AUTOSAR XML (schema 4-0-3)
standard types defined: Boolean, uint8, UInt16, UInt32, UInt8
package /AUTOSAR_Platform/DataConstrs
  range DC_Boolean: raw 0..1
  range DC_UInt16: raw 0..65535
  range DC_UInt8: raw 0..255
package /PATAC/Facility/DataTypes/Implementation
  compu method COMPU_Boolean: 0=FALSE, 1=TRUE
  unit NoUnit: factor-si-to-unit=1, offset-si-to-unit=0
package /PATAC/MSM/ComponentTypes
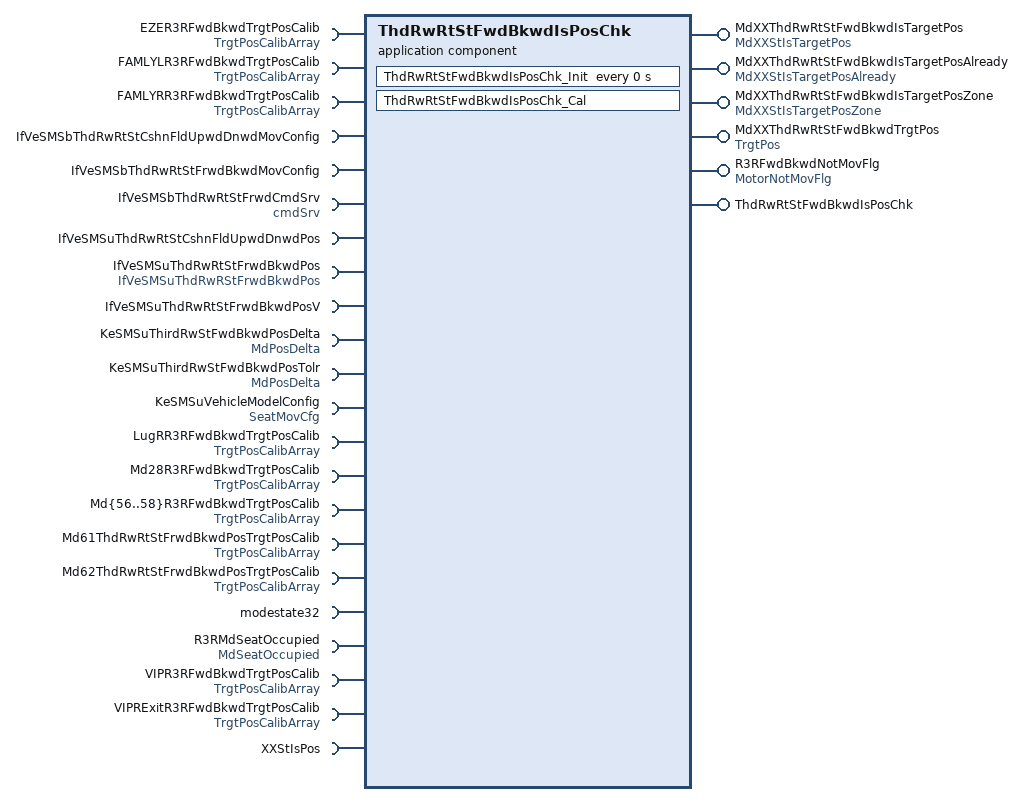
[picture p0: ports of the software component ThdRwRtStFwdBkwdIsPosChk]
  application sw component type ThdRwRtStFwdBkwdIsPosChk
    6 x provide port:
      MdXXThdRwRtStFwdBkwdIsTargetPos: nonqueued-sender-com-spec=data-element=MdXXStIsTargetPos/Val, provided-interface=MdXXStIsTargetPos
      MdXXThdRwRtStFwdBkwdIsTargetPosAlready: nonqueued-sender-com-spec=data-element=MdXXStIsTargetPosAlready/Val, provided-interface=MdXXStIsTargetPosAlready
      MdXXThdRwRtStFwdBkwdIsTargetPosZone: nonqueued-sender-com-spec=data-element=MdXXStIsTargetPosZone/Val, provided-interface=MdXXStIsTargetPosZone
      MdXXThdRwRtStFwdBkwdTrgtPos: nonqueued-sender-com-spec{data-element=TrgtPos/Val, init-value=4095}, provided-interface=TrgtPos
      R3RFwdBkwdNotMovFlg: nonqueued-sender-com-spec{data-element=MotorNotMovFlg/Val, init-value=0}, provided-interface=MotorNotMovFlg
      ThdRwRtStFwdBkwdIsPosChk: server-com-spec{operation=Cal, queue-length=1}, provided-interface=ThdRwRtStFwdBkwdIsPosChk
    24 x require port:
      EZER3RFwdBkwdTrgtPosCalib: nonqueued-receiver-com-spec{data-element=TrgtPosArray, filter=data-filter-type=ALWAYS, init-value=[4095, 4095, 4095]}, required-interface=TrgtPosCalibArray
      FAMLYLR3RFwdBkwdTrgtPosCalib: nonqueued-receiver-com-spec{data-element=TrgtPosArray, filter=data-filter-type=ALWAYS, init-value=[4095, 4095, 4095]}, required-interface=TrgtPosCalibArray
      FAMLYRR3RFwdBkwdTrgtPosCalib: nonqueued-receiver-com-spec{data-element=TrgtPosArray, filter=data-filter-type=ALWAYS, init-value=[4095, 4095, 4095]}, required-interface=TrgtPosCalibArray
      IfVeSMSbThdRwRtStCshnFldUpwdDnwdMovConfig: nonqueued-receiver-com-spec{data-element=IfVeSMSbThdRwRtStCshnFldUpwdDnwdMovConfig/Val, filter=data-filter-type=ALWAYS, init-value=0}, required-interface=IfVeSMSbThdRwRtStCshnFldUpwdDnwdMovConfig
      IfVeSMSbThdRwRtStFrwdBkwdMovConfig: nonqueued-receiver-com-spec{data-element=IfVeSMSbThdRwRtStFrwdBkwdMovConfig/Val, filter=data-filter-type=ALWAYS, init-value=0}, required-interface=IfVeSMSbThdRwRtStFrwdBkwdMovConfig
      IfVeSMSbThdRwRtStFrwdCmdSrv: nonqueued-receiver-com-spec{data-element=cmdSrv/Val, filter=data-filter-type=ALWAYS, init-value=1}, required-interface=cmdSrv
      IfVeSMSuThdRwRtStCshnFldUpwdDnwdPos: nonqueued-receiver-com-spec{data-element=IfVeSMSuThdRwRtStCshnFldUpwdDnwdPos/Val, filter=data-filter-type=ALWAYS, init-value=0}, required-interface=IfVeSMSuThdRwRtStCshnFldUpwdDnwdPos
      IfVeSMSuThdRwRtStFrwdBkwdPos: nonqueued-receiver-com-spec{data-element=IfVeSMSuThdRwRStFrwdBkwdPos/Val, filter=data-filter-type=ALWAYS, init-value=0}, required-interface=IfVeSMSuThdRwRStFrwdBkwdPos
      IfVeSMSuThdRwRtStFrwdBkwdPosV: nonqueued-receiver-com-spec{data-element=IfVeSMSuThdRwRtStFrwdBkwdPosV/Val, filter=data-filter-type=ALWAYS, init-value=0}, required-interface=IfVeSMSuThdRwRtStFrwdBkwdPosV
      KeSMSuThirdRwStFwdBkwdPosDelta: parameter-require-com-spec{init-value=150, parameter=MdPosDelta/Val}, required-interface=MdPosDelta
      KeSMSuThirdRwStFwdBkwdPosTolr: parameter-require-com-spec{init-value=150, parameter=MdPosDelta/Val}, required-interface=MdPosDelta
      KeSMSuVehicleModelConfig: parameter-require-com-spec{init-value=2, parameter=SeatMovCfg/Val}, required-interface=SeatMovCfg
      LugRR3RFwdBkwdTrgtPosCalib: nonqueued-receiver-com-spec{data-element=TrgtPosArray, filter=data-filter-type=ALWAYS, init-value=[4095, 4095, 4095]}, required-interface=TrgtPosCalibArray
      Md28R3RFwdBkwdTrgtPosCalib: nonqueued-receiver-com-spec{data-element=TrgtPosArray, filter=data-filter-type=ALWAYS, init-value=[4095, 4095, 4095]}, required-interface=TrgtPosCalibArray
      Md{56..58}R3RFwdBkwdTrgtPosCalib: nonqueued-receiver-com-spec{data-element=TrgtPosArray, filter=data-filter-type=ALWAYS, init-value=[4095, 4095, 4095]}, required-interface=TrgtPosCalibArray
      Md61ThdRwRtStFrwdBkwdPosTrgtPosCalib: nonqueued-receiver-com-spec{data-element=TrgtPosArray, filter=data-filter-type=ALWAYS, init-value=[4095, 4095, 4095]}, required-interface=TrgtPosCalibArray
      Md62ThdRwRtStFrwdBkwdPosTrgtPosCalib: nonqueued-receiver-com-spec{data-element=TrgtPosArray, filter=data-filter-type=ALWAYS, init-value=[4095, 4095, 4095]}, required-interface=TrgtPosCalibArray
      modestate32: nonqueued-receiver-com-spec{data-element=modestate32/Val, filter=data-filter-type=ALWAYS, init-value=0}, required-interface=modestate32
      R3RMdSeatOccupied: nonqueued-receiver-com-spec{data-element=MdSeatOccupied/Val, filter=data-filter-type=ALWAYS, init-value=0}, required-interface=MdSeatOccupied
      VIPR3RFwdBkwdTrgtPosCalib: nonqueued-receiver-com-spec{data-element=TrgtPosArray, filter=data-filter-type=ALWAYS, init-value=[4095, 4095, 4095]}, required-interface=TrgtPosCalibArray
      VIPRExitR3RFwdBkwdTrgtPosCalib: nonqueued-receiver-com-spec{data-element=TrgtPosArray, filter=data-filter-type=ALWAYS, init-value=[4095, 4095, 4095]}, required-interface=TrgtPosCalibArray
      XXStIsPos: client-com-spec=Get, required-interface=XXStIsPos
    behavior ThdRwRtStFwdBkwdIsPosChk_InternalBehavior
      operation invoked event OIT_ThdRwRtStFwdBkwdIsPosChk_Cal_ThdRwRtStFwdBkwdIsPosChk_Cal: start-on-event=ThdRwRtStFwdBkwdIsPosChk_Cal, operation=ThdRwRtStFwdBkwdIsPosChk.Cal
      timing event ThdRwRtStFwdBkwdIsPosChk_InitEvent: start-on-event=ThdRwRtStFwdBkwdIsPosChk_Init, period=0
      runnable ThdRwRtStFwdBkwdIsPosChk_Cal
        data-receive-point-by-arguments:
          20 x access:
            REC_EZER3RFwdBkwdTrgtPosCalib_TrgtPosArray: accessed-variable=EZER3RFwdBkwdTrgtPosCalib.TrgtPosArray
            REC_FAMLYLR3RFwdBkwdTrgtPosCalib_TrgtPosArray: accessed-variable=FAMLYLR3RFwdBkwdTrgtPosCalib.TrgtPosArray
            REC_FAMLYRR3RFwdBkwdTrgtPosCalib_TrgtPosArray: accessed-variable=FAMLYRR3RFwdBkwdTrgtPosCalib.TrgtPosArray
            REC_IfVeSMSbThdRwRtStCshnFldUpwdDnwdMovConfig_Val: accessed-variable=IfVeSMSbThdRwRtStCshnFldUpwdDnwdMovConfig.Val
            REC_IfVeSMSbThdRwRtStFrwdBkwdMovConfig_Val: accessed-variable=IfVeSMSbThdRwRtStFrwdBkwdMovConfig.Val
            REC_IfVeSMSbThdRwRtStFrwdCmdSrv_Val: accessed-variable=IfVeSMSbThdRwRtStFrwdCmdSrv.Val
            REC_IfVeSMSuThdRwRtStCshnFldUpwdDnwdPos_Val: accessed-variable=IfVeSMSuThdRwRtStCshnFldUpwdDnwdPos.Val
            REC_IfVeSMSuThdRwRtStFrwdBkwdPos_Val: accessed-variable=IfVeSMSuThdRwRtStFrwdBkwdPos.Val
            REC_IfVeSMSuThdRwRtStFrwdBkwdPosV_Val: accessed-variable=IfVeSMSuThdRwRtStFrwdBkwdPosV.Val
            REC_LugRR3RFwdBkwdTrgtPosCalib_TrgtPosArray: accessed-variable=LugRR3RFwdBkwdTrgtPosCalib.TrgtPosArray
            REC_Md28R3RFwdBkwdTrgtPosCalib_TrgtPosArray: accessed-variable=Md28R3RFwdBkwdTrgtPosCalib.TrgtPosArray
            REC_Md{56..58}R3RFwdBkwdTrgtPosCalib_TrgtPosArray: accessed-variable=Md{56..58}R3RFwdBkwdTrgtPosCalib.TrgtPosArray
            REC_Md61ThdRwRtStFrwdBkwdPosTrgtPosCalib_TrgtPosArray: accessed-variable=Md61ThdRwRtStFrwdBkwdPosTrgtPosCalib.TrgtPosArray
            REC_Md62ThdRwRtStFrwdBkwdPosTrgtPosCalib_TrgtPosArray: accessed-variable=Md62ThdRwRtStFrwdBkwdPosTrgtPosCalib.TrgtPosArray
            REC_modestate32_Val: accessed-variable=modestate32.Val
            REC_R3RMdSeatOccupied_Val: accessed-variable=R3RMdSeatOccupied.Val
            REC_VIPR3RFwdBkwdTrgtPosCalib_TrgtPosArray: accessed-variable=VIPR3RFwdBkwdTrgtPosCalib.TrgtPosArray
            REC_VIPRExitR3RFwdBkwdTrgtPosCalib_TrgtPosArray: accessed-variable=VIPRExitR3RFwdBkwdTrgtPosCalib.TrgtPosArray
        data-send-points:
          5 x access:
            SEND_MdXXThdRwRtStFwdBkwdIsTargetPos_Val: accessed-variable=MdXXThdRwRtStFwdBkwdIsTargetPos.Val
            SEND_MdXXThdRwRtStFwdBkwdIsTargetPosAlready_Val: accessed-variable=MdXXThdRwRtStFwdBkwdIsTargetPosAlready.Val
            SEND_MdXXThdRwRtStFwdBkwdIsTargetPosZone_Val: accessed-variable=MdXXThdRwRtStFwdBkwdIsTargetPosZone.Val
            SEND_MdXXThdRwRtStFwdBkwdTrgtPos_Val: accessed-variable=MdXXThdRwRtStFwdBkwdTrgtPos.Val
            SEND_R3RFwdBkwdNotMovFlg_Val: accessed-variable=R3RFwdBkwdNotMovFlg.Val
        parameter access PA_KeSMSuThirdRwStFwdBkwdPosDelta_Val: accessed-parameter=KeSMSuThirdRwStFwdBkwdPosDelta.Val
        parameter access PA_KeSMSuThirdRwStFwdBkwdPosTolr_Val: accessed-parameter=KeSMSuThirdRwStFwdBkwdPosTolr.Val
        parameter access PA_KeSMSuVehicleModelConfig_Val: accessed-parameter=KeSMSuVehicleModelConfig.Val
        sync call SC_XXStIsPos_Get: operation=XXStIsPos.Get, timeout=0
      runnable ThdRwRtStFwdBkwdIsPosChk_Init
        parameter access PA_KeSMSuThirdRwStFwdBkwdPosDelta_Val: accessed-parameter=KeSMSuThirdRwStFwdBkwdPosDelta.Val
        parameter access PA_KeSMSuThirdRwStFwdBkwdPosTolr_Val: accessed-parameter=KeSMSuThirdRwStFwdBkwdPosTolr.Val
        parameter access PA_KeSMSuVehicleModelConfig_Val: accessed-parameter=KeSMSuVehicleModelConfig.Val
  swc implementation ThdRwRtStFwdBkwdIsPosChk_Implementation: behavior=ThdRwRtStFwdBkwdIsPosChk_InternalBehavior
    code-descriptors:
      code Default: artifact-descriptors=autosar-engineering-object={short-label=Default, category=SWSRC}
package /PATAC/MSM/DataTypes
  parameter interface SeatMovCfg
    parameter data prototype Val: sw-calibration-access=READ-WRITE, type=UInt8
package /PATAC/MSM/Intervene/PortInterfaces
  sender receiver interface cmdSrv: invalidation-policy{data-element=cmdSrv/Val, handle-invalid=DONT-INVALIDATE}
    data Val: type=Implementation/Boolean
package /PATAC/MSM/ModeAdjust/CalPortInterface
  parameter interface MdPosDelta
    parameter data prototype Val: sw-calibration-access=READ-WRITE, type=UInt16
package /PATAC/MSM/ModeAdjust/DataType
  impl type TrgtPosCalibArray: category=ARRAY, sw-calibration-access=READ-ONLY, type-emitter=RTE  # 0:pos 1:max 2:min
    element Element: array-size=3, array-size-semantics=FIXED-SIZE, implementation-data-type=UInt16, invalid-value=0
package /PATAC/MSM/ModeAdjust/Interfaces
  sender receiver interface IfVeSMSuThdRwRtStCshnFldUpwdDnwdPos: invalidation-policy{data-element=IfVeSMSuThdRwRtStCshnFldUpwdDnwdPos/Val, handle-invalid=DONT-INVALIDATE}
    data Val: type=UInt16
  sender receiver interface IfVeSMSuThdRwRtStFrwdBkwdPosV: invalidation-policy{data-element=IfVeSMSuThdRwRtStFrwdBkwdPosV/Val, handle-invalid=DONT-INVALIDATE}
    data Val: type=Implementation/Boolean
package /PATAC/MSM/ModeAdjust/PortInterface
  client server interface ThdRwRtStFwdBkwdIsPosChk
    operation Cal
  client server interface XXStIsPos
    operation Get
      8 x arg, all with server-argument-impl-policy=USE-ARGUMENT-TYPE:
        PosV: type=DataTypes/Boolean, direction=IN
        Pos: type=UInt16, direction=IN
        CalibArray: type=TrgtPosCalibArray, direction=IN
        Delta: type=UInt16, direction=IN
        Tolr: type=UInt16, direction=IN
        IsPos: type=DataTypes/Boolean, direction=OUT
        IsPosZone: type=DataTypes/Boolean, direction=OUT
        IsPosAlready: type=DataTypes/Boolean, direction=OUT
  7 x sender receiver interface:
    MdSeatOccupied: invalidation-policy{data-element=MdSeatOccupied/Val, handle-invalid=DONT-INVALIDATE}
      data Val: type=Implementation/Boolean
    MdXXStIsTargetPos: invalidation-policy{data-element=MdXXStIsTargetPos/Val, handle-invalid=DONT-INVALIDATE}
      data Val: type=UInt32
    MdXXStIsTargetPosAlready: invalidation-policy{data-element=MdXXStIsTargetPosAlready/Val, handle-invalid=DONT-INVALIDATE}
      data Val: type=UInt32
    MdXXStIsTargetPosZone: invalidation-policy{data-element=MdXXStIsTargetPosZone/Val, handle-invalid=DONT-INVALIDATE}
      data Val: type=UInt32
    modestate32: invalidation-policy{data-element=modestate32/Val, handle-invalid=DONT-INVALIDATE}
      data Val: type=UInt32
    MotorNotMovFlg: invalidation-policy{data-element=MotorNotMovFlg/Val, handle-invalid=DONT-INVALIDATE}
      data Val: type=Implementation/Boolean
    TrgtPosCalibArray: invalidation-policy{data-element=TrgtPosArray, handle-invalid=DONT-INVALIDATE}
      data TrgtPosArray: type=TrgtPosCalibArray  # 0:Pos 1:Max 2:Min
package /PATAC/MSM/PortInterfaces
  4 x sender receiver interface:
    IfVeSMSbThdRwRtStCshnFldUpwdDnwdMovConfig: invalidation-policy{data-element=IfVeSMSbThdRwRtStCshnFldUpwdDnwdMovConfig/Val, handle-invalid=DONT-INVALIDATE}
      data Val: type=Implementation/Boolean
    IfVeSMSbThdRwRtStFrwdBkwdMovConfig: invalidation-policy{data-element=IfVeSMSbThdRwRtStFrwdBkwdMovConfig/Val, handle-invalid=DONT-INVALIDATE}
      data Val: type=Implementation/Boolean
    IfVeSMSuThdRwRStFrwdBkwdPos: invalidation-policy{data-element=IfVeSMSuThdRwRStFrwdBkwdPos/Val, handle-invalid=DONT-INVALIDATE}
      data Val: type=UInt16
    TrgtPos: invalidation-policy{data-element=TrgtPos/Val, handle-invalid=DONT-INVALIDATE}
      data Val: type=UInt16
